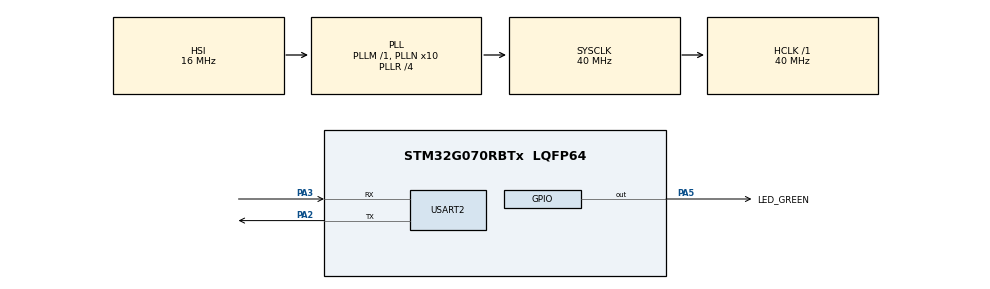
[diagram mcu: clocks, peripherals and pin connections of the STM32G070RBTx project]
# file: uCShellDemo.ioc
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FREERTOS.Tasks01=defaultTask,24,128,StartDefaultTask,Default,NULL,Dynamic,NULL,NULL;RxTask,48,128,RxReceive,As weak,NULL,Dynamic,NULL,NULL;uC_Shell_exec,40,256,Terminal_Task,As weak,NULL,Dynamic,NULL,NULL
Mcu.Family=STM32G0
Mcu.Name=STM32G070RBTx
Mcu.Package=LQFP64
NVIC.TIM17_IRQn=true\:0\:0\:false\:false\:true\:false\:false\:true
NVIC.TimeBase=TIM17_IRQn
NVIC.TimeBaseIP=TIM17
NVIC.USART2_IRQn=true\:3\:0\:true\:false\:true\:true\:true\:true
PA13.GPIO_Label=TMS
PA13.Mode=Serial_Wire
PA13.Signal=SYS_SWDIO
PA14-BOOT0.GPIO_Label=TCK
PA14-BOOT0.Mode=Serial_Wire
PA14-BOOT0.Signal=SYS_SWCLK
PA2.GPIO_PuPd=GPIO_PULLUP
PA2.Mode=Asynchronous
PA2.Signal=USART2_TX
PA3.GPIO_PuPd=GPIO_PULLUP
PA3.Mode=Asynchronous
PA3.Signal=USART2_RX
PA5.GPIO_Label=LED_GREEN
PA5.GPIO_Speed=GPIO_SPEED_FREQ_HIGH
PA5.Signal=GPIO_Output
PC13.Mode=SYS_WakeUp1
PC13.Signal=SYS_WKUP2
PC14-OSC32_IN\ (PC14).Mode=LSE-External-Oscillator
PC14-OSC32_IN\ (PC14).Signal=RCC_OSC32_IN
PC15-OSC32_OUT\ (PC15).Mode=LSE-External-Oscillator
PC15-OSC32_OUT\ (PC15).Signal=RCC_OSC32_OUT
PF0-OSC_IN\ (PF0).GPIO_Label=MCO
PF0-OSC_IN\ (PF0).Mode=HSE-External-Clock-Source
PF0-OSC_IN\ (PF0).Signal=RCC_OSC_IN
ProjectManager.HeapSize=0x200
ProjectManager.StackSize=0x400
ProjectManager.TargetToolchain=EWARM V8.32
RCC.ADCFreq_Value=40000000
RCC.AHBFreq_Value=40000000
RCC.CortexFreq_Value=40000000
RCC.EXTERNAL_CLOCK_VALUE=12288000
RCC.HCLKFreq_Value=40000000
RCC.HSE_VALUE=8000000
RCC.HSI_VALUE=16000000
RCC.PLLN=10
RCC.PLLR=RCC_PLLR_DIV4
RCC.SYSCLKFreq_VALUE=40000000
RCC.SYSCLKSource=RCC_SYSCLKSOURCE_PLLCLK
RCC.VCOOutputFreq_Value=160000000
USART2.DMADisableonRxErrorParam=ADVFEATURE_DMA_DISABLEONRXERROR
USART2.OneBitSampling=UART_ONE_BIT_SAMPLE_DISABLE
USART2.OverSampling=UART_OVERSAMPLING_8
USART2.OverrunDisableParam=ADVFEATURE_OVERRUN_DISABLE
USART2.VirtualMode-Asynchronous=VM_ASYNC
USART2.WordLength=WORDLENGTH_8B
VP_FREERTOS_VS_CMSIS_V2.Mode=CMSIS_V2
VP_SYS_VS_DBSignals.Mode=DisableDeadBatterySignals
VP_SYS_VS_tim17.Mode=TIM17
board=NUCLEO-G070RB

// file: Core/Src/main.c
/* USER CODE BEGIN Header */
/**
  ******************************************************************************
  * @file           : main.c
  * @brief          : Main program body
  ******************************************************************************
  * @attention
  *
  * <h2><center>&copy; Copyright (c) 2020 STMicroelectronics.
  * All rights reserved.</center></h2>
  *
  * This software component is licensed by ST under Ultimate Liberty license
  * SLA0044, the "License"; You may not use this file except in compliance with
  * the License. You may obtain a copy of the License at:
  *                             www.st.com/SLA0044
  *
  ******************************************************************************
  */
/* USER CODE END Header */

#include "main.h"
#include "cmsis_os.h"
#include "usart.h"
#include "gpio.h"

void SystemClock_Config(void);
void MX_FREERTOS_Init(void);

int main(void)
{

  /* MCU Configuration--------------------------------------------------------*/

  /* Reset of all peripherals, Initializes the Flash interface and the Systick. */
  HAL_Init();

  /* Configure the system clock */
  SystemClock_Config();

  /* Initialize all configured peripherals */
  MX_GPIO_Init();
  MX_USART2_UART_Init();

  /* Init scheduler */
  osKernelInitialize();  /* Call init function for freertos objects (in freertos.c) */
  MX_FREERTOS_Init();
  /* Start scheduler */
  osKernelStart();

  /* We should never get here as control is now taken by the scheduler */
  /* Infinite loop */
  while (1)
  {

  }
}

void SystemClock_Config(void)
{
  RCC_OscInitTypeDef RCC_OscInitStruct = {0};
  RCC_ClkInitTypeDef RCC_ClkInitStruct = {0};
  RCC_PeriphCLKInitTypeDef PeriphClkInit = {0};

  /** Configure the main internal regulator output voltage
  */
  HAL_PWREx_ControlVoltageScaling(PWR_REGULATOR_VOLTAGE_SCALE1);
  /** Initializes the CPU, AHB and APB busses clocks
  */
  RCC_OscInitStruct.OscillatorType = RCC_OSCILLATORTYPE_HSI;
  RCC_OscInitStruct.HSIState = RCC_HSI_ON;
  RCC_OscInitStruct.HSIDiv = RCC_HSI_DIV1;
  RCC_OscInitStruct.HSICalibrationValue = RCC_HSICALIBRATION_DEFAULT;
  RCC_OscInitStruct.PLL.PLLState = RCC_PLL_ON;
  RCC_OscInitStruct.PLL.PLLSource = RCC_PLLSOURCE_HSI;
  RCC_OscInitStruct.PLL.PLLM = RCC_PLLM_DIV1;
  RCC_OscInitStruct.PLL.PLLN = 10;
  RCC_OscInitStruct.PLL.PLLP = RCC_PLLP_DIV2;
  RCC_OscInitStruct.PLL.PLLR = RCC_PLLR_DIV4;
  if (HAL_RCC_OscConfig(&RCC_OscInitStruct) != HAL_OK)
  {
    Error_Handler();
  }
  /** Initializes the CPU, AHB and APB busses clocks
  */
  RCC_ClkInitStruct.ClockType = RCC_CLOCKTYPE_HCLK|RCC_CLOCKTYPE_SYSCLK
                              |RCC_CLOCKTYPE_PCLK1;
  RCC_ClkInitStruct.SYSCLKSource = RCC_SYSCLKSOURCE_PLLCLK;
  RCC_ClkInitStruct.AHBCLKDivider = RCC_SYSCLK_DIV1;
  RCC_ClkInitStruct.APB1CLKDivider = RCC_HCLK_DIV1;

  if (HAL_RCC_ClockConfig(&RCC_ClkInitStruct, FLASH_LATENCY_1) != HAL_OK)
  {
    Error_Handler();
  }
  /** Initializes the peripherals clocks
  */
  PeriphClkInit.PeriphClockSelection = RCC_PERIPHCLK_USART2;
  PeriphClkInit.Usart2ClockSelection = RCC_USART2CLKSOURCE_PCLK1;
  if (HAL_RCCEx_PeriphCLKConfig(&PeriphClkInit) != HAL_OK)
  {
    Error_Handler();
  }
}

 /**
  * @brief  Period elapsed callback in non blocking mode
  * @note   This function is called  when TIM17 interrupt took place, inside
  * HAL_TIM_IRQHandler(). It makes a direct call to HAL_IncTick() to increment
  * a global variable "uwTick" used as application time base.
  * @param  htim : TIM handle
  * @retval None
  */
void HAL_TIM_PeriodElapsedCallback(TIM_HandleTypeDef *htim)
{
  if (htim->Instance == TIM17) {
    HAL_IncTick();
  }
}

void Error_Handler(void)
{
}

/************************ (C) COPYRIGHT STMicroelectronics *****END OF FILE****/

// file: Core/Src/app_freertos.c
/* USER CODE BEGIN Header */
/**
  ******************************************************************************
  * File Name          : app_freertos.c
  * Description        : Code for freertos applications
  ******************************************************************************
  * @attention
  *
  * <h2><center>&copy; Copyright (c) 2020 STMicroelectronics.
  * All rights reserved.</center></h2>
  *
  * This software component is licensed by ST under Ultimate Liberty license
  * SLA0044, the "License"; You may not use this file except in compliance with
  * the License. You may obtain a copy of the License at:
  *                             www.st.com/SLA0044
  *
  ******************************************************************************
  */
/* USER CODE END Header */

#include "FreeRTOS.h"
#include "task.h"
#include "main.h"
#include "cmsis_os.h"

/* USER CODE BEGIN Includes */

/* Demo app includes. */

#include "includes.h"

/* USER CODE END Includes */

/* Definitions for defaultTask */
osThreadId_t defaultTaskHandle;
const osThreadAttr_t defaultTask_attributes = {
  .name = "defaultTask",
  .priority = (osPriority_t) osPriorityNormal,
  .stack_size = 128 * 4
};
/* Definitions for RxTask */
osThreadId_t RxTaskHandle;
const osThreadAttr_t RxTask_attributes = {
  .name = "RxTask",
  .priority = (osPriority_t) osPriorityRealtime,
  .stack_size = 128 * 4
};
/* Definitions for uC_Shell_exec */
osThreadId_t uC_Shell_execHandle;
const osThreadAttr_t uC_Shell_exec_attributes = {
  .name = "uC_Shell_exec",
  .priority = (osPriority_t) osPriorityHigh,
  .stack_size = 256 * 4
};

void StartDefaultTask(void *argument);
void RxReceive(void *argument);
void Terminal_Task(void *argument);

void MX_FREERTOS_Init(void); /* (MISRA C 2004 rule 8.1) */

void MX_FREERTOS_Init(void) {

  /* Create the thread(s) */
  /* creation of defaultTask */
  defaultTaskHandle = osThreadNew(StartDefaultTask, NULL, &defaultTask_attributes);

  /* creation of RxTask */
  RxTaskHandle = osThreadNew(RxReceive, NULL, &RxTask_attributes);

  /* creation of uC_Shell_exec */
  uC_Shell_execHandle = osThreadNew(Terminal_Task, NULL, &uC_Shell_exec_attributes);

  /* USER CODE BEGIN RTOS_THREADS */
  /* add threads, ... */

  vStartStreamBufferInit();

  /* USER CODE END RTOS_THREADS */

}

void StartDefaultTask(void *argument)
{
  for(;;)
  {
    osDelay(1);
  }
}

__weak void RxReceive(void *argument)
{
  /* USER CODE BEGIN RxReceive */
  /* Infinite loop */
  for(;;)
  {
    osDelay(100);
  }
  /* USER CODE END RxReceive */
}

__weak void Terminal_Task(void *argument)
{
  for(;;)
  {
    osDelay(1);
  }
}

/************************ (C) COPYRIGHT STMicroelectronics *****END OF FILE****/
